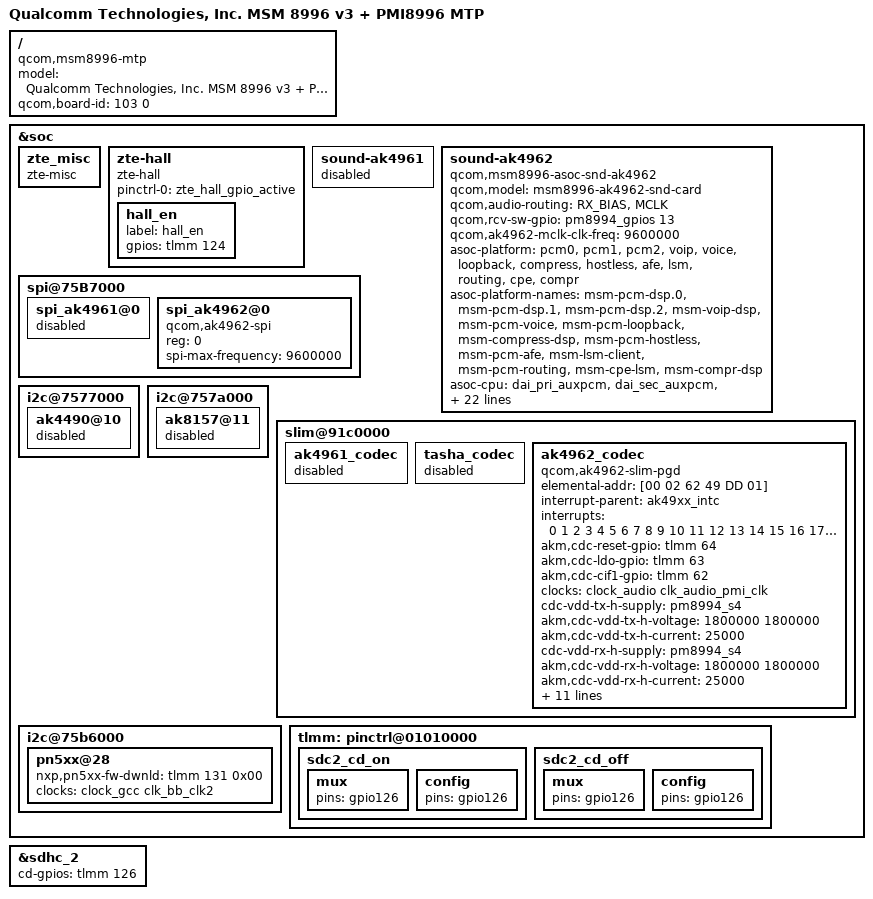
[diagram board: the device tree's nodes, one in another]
/* Copyright (c) 2015, The Linux Foundation. All rights reserved.
 *
 * This program is free software; you can redistribute it and/or modify
 * it under the terms of the GNU General Public License version 2 and
 * only version 2 as published by the Free Software Foundation.
 *
 * This program is distributed in the hope that it will be useful,
 * but WITHOUT ANY WARRANTY; without even the implied warranty of
 * MERCHANTABILITY or FITNESS FOR A PARTICULAR PURPOSE.  See the
 * GNU General Public License for more details.
 */


/dts-v1/;

#include "msm8996pro-v1.1.dtsi"
#include "msm-pmi8996.dtsi"
#include "msm8996-mtp.dtsi"

#include "zte-msm8996pro-v1.1-pmi8996-candice.dtsi"

/ {
	model = "Qualcomm Technologies, Inc. MSM 8996 v3 + PMI8996 MTP";
	compatible = "qcom,msm8996-mtp", "qcom,msm8996", "qcom,mtp";
	qcom,board-id = <103 0>;
};
&soc {
	zte_misc {
		compatible = "zte-misc";
	};

	zte-hall {
		compatible = "zte-hall";
		pinctrl-names = "zte_hall_gpio_active";
		pinctrl-0 = <&zte_hall_gpio_active>;
		hall_en{
			label = "hall_en";
			gpios = <&tlmm 124 0x0>;
		};
	};

	sound-ak4961 {
		status = "disabled";
	};

	sound-ak4962 {
		compatible = "qcom,msm8996-asoc-snd-ak4962";
		qcom,model = "msm8996-ak4962-snd-card";

		qcom,audio-routing =
			"RX_BIAS", "MCLK";

		qcom,rcv-sw-gpio = <&pm8994_gpios 13 0>;

		qcom,ak4962-mclk-clk-freq = <9600000>;
		asoc-platform = <&pcm0>, <&pcm1>, <&pcm2>, <&voip>, <&voice>,
				<&loopback>, <&compress>, <&hostless>,
				<&afe>, <&lsm>, <&routing>, <&cpe>, <&compr>;
		asoc-platform-names = "msm-pcm-dsp.0", "msm-pcm-dsp.1", "msm-pcm-dsp.2",
				"msm-voip-dsp", "msm-pcm-voice", "msm-pcm-loopback",
				"msm-compress-dsp", "msm-pcm-hostless", "msm-pcm-afe",
				"msm-lsm-client", "msm-pcm-routing", "msm-cpe-lsm",
				"msm-compr-dsp";
		asoc-cpu = <&dai_pri_auxpcm>, <&dai_sec_auxpcm>, <&dai_hdmi>, <&dai_mi2s>,<&dai_mi2s_quat>,
				<&sb_0_rx>, <&sb_0_tx>, <&sb_1_rx>, <&sb_1_tx>,
				<&sb_2_rx>, <&sb_2_tx>, <&sb_3_rx>, <&sb_3_tx>,
				<&sb_4_rx>, <&sb_4_tx>, <&sb_5_tx>, <&afe_pcm_rx>,
				<&afe_pcm_tx>, <&afe_proxy_rx>, <&afe_proxy_tx>,
				<&incall_record_rx>, <&incall_record_tx>,
				<&incall_music_rx>, <&incall_music2_rx>,
				<&sb_5_rx>;
		asoc-cpu-names = "msm-dai-q6-auxpcm.1", "msm-dai-q6-auxpcm.2",
				"msm-dai-q6-hdmi.8", "msm-dai-q6-mi2s.2","msm-dai-q6-mi2s.3",
				"msm-dai-q6-dev.16384", "msm-dai-q6-dev.16385",
				"msm-dai-q6-dev.16386", "msm-dai-q6-dev.16387",
				"msm-dai-q6-dev.16388", "msm-dai-q6-dev.16389",
				"msm-dai-q6-dev.16390", "msm-dai-q6-dev.16391",
				"msm-dai-q6-dev.16392", "msm-dai-q6-dev.16393",
				"msm-dai-q6-dev.16395", "msm-dai-q6-dev.224",
				"msm-dai-q6-dev.225", "msm-dai-q6-dev.241",
				"msm-dai-q6-dev.240", "msm-dai-q6-dev.32771",
				"msm-dai-q6-dev.32772", "msm-dai-q6-dev.32773",
				"msm-dai-q6-dev.32770", "msm-dai-q6-dev.16394";
		asoc-codec = <&stub_codec>;
		asoc-codec-names = "msm-stub-codec.1";
	};

	spi@75B7000 {
		spi_ak4961@0 {
			status = "disabled";
		};

		spi_ak4962@0{
			compatible = "qcom,ak4962-spi";
			reg=<0>;
			spi-max-frequency = <9600000>;
		};
	};

	i2c@7577000 {
		ak4490@10 {
			status = "disabled";
		};
	};

	i2c@757a000 {
		ak8157@11 {
			status = "disabled";
		};
	};

	slim@91c0000 {
		ak4961_codec {
			status = "disabled";
		};

		tasha_codec {
			status = "disabled";
		};

		ak4962_codec {
			compatible = "qcom,ak4962-slim-pgd";
			elemental-addr = [00 02 62 49 DD 01];

			interrupt-parent = <&ak49xx_intc>;
			interrupts = <0 1 2 3 4 5 6 7 8 9 10 11 12 13 14 15 16
				      17 18 19 20 21 22 23 24 25 26 27 28 29
				      30 31>;

			akm,cdc-reset-gpio = <&tlmm 64 0>;
			akm,cdc-ldo-gpio = <&tlmm 63 0>;
			akm,cdc-cif1-gpio = <&tlmm 62 0>;

			clock-names = "cdc_clk";
			clocks = <&clock_audio clk_audio_pmi_clk>;

			/* cdc-vdd-buck-supply = <&pm8994_s4>;*/
			/* qcom,cdc-vdd-buck-voltage = <1800000 1800000>;*/
			/* qcom,cdc-vdd-buck-current = <650000>;*/

			cdc-vdd-tx-h-supply = <&pm8994_s4>;
			akm,cdc-vdd-tx-h-voltage = <1800000 1800000>;
			akm,cdc-vdd-tx-h-current = <25000>;

			cdc-vdd-rx-h-supply = <&pm8994_s4>;
			akm,cdc-vdd-rx-h-voltage = <1800000 1800000>;
			akm,cdc-vdd-rx-h-current = <25000>;

			cdc-vdd-px-supply = <&pm8994_s4>;
			akm,cdc-vdd-px-voltage = <1800000 1800000>;
			akm,cdc-vdd-px-current = <45000>;

			akm,cdc-static-supplies = "cdc-vdd-tx-h",
						   "cdc-vdd-rx-h",
						   "cdc-vdd-px";

			akm,cdc-micbias-mpwr1-mv = <0>;
			akm,cdc-micbias-mpwr2-mv = <2800>;

			akm,cdc-mclk-clk-rate = <9600000>;
			akm,cdc-slim-ifd = "ak4962-slim-ifd";
			akm,cdc-slim-ifd-elemental-addr = [00 00 62 49 DD 01];
		};
	};
	i2c@75b6000 { /* BLSP2 QUP2 */
		pn5xx@28{
			nxp,pn5xx-fw-dwnld = <&tlmm 131 0x00>;
			clocks = <&clock_gcc clk_bb_clk2>;
			clock-names = "bb_clk2";
		};
	};

	tlmm: pinctrl@01010000 {
		sdc2_cd_on: sdc2_cd_on {
			mux {
				pins = "gpio126";
			};

			config {
				pins = "gpio126";
			};
		};

		sdc2_cd_off: sdc2_cd_off {
			mux {
				pins = "gpio126";
			};

			config {
				pins = "gpio126";
			};
		};
	};
};

&sdhc_2 {
	cd-gpios = <&tlmm 126 0x0>;
};

/*delete the gpio131 because it influe the nfc download gpio*/
/*&pcie1_clkreq_default {
	mux {
		pins = "gpio130";
	};

	config {
		pins = "gpio130";
	};
};
&pcie1_clkreq_sleep {
	mux {
		pins = "gpio130";
	};

	config {
		pins = "gpio130";
	};
};*/
